VERSION ""

NS_ :

BS_:

BU_: TCU CANedge BMS TempSense

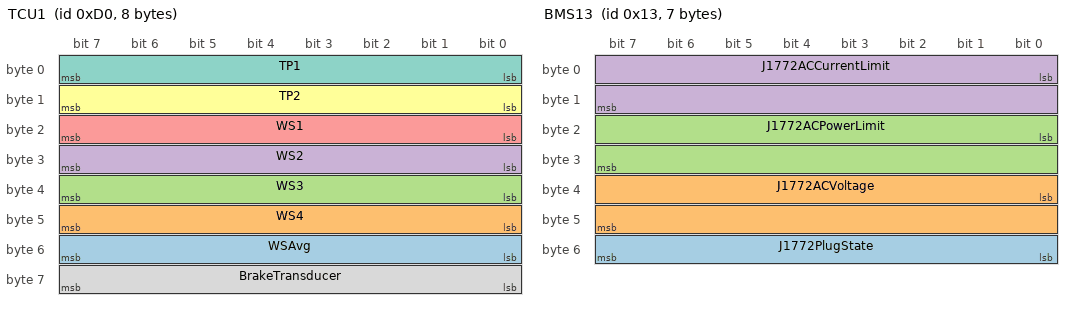
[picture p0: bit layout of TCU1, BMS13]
BO_ 208 TCU1: 8 TCU
 SG_ WSAvg : 48|8@1+ (1,0) [0|255] ""  CANedge
 SG_ WS4 : 40|8@1+ (1,0) [0|255] ""  CANedge
 SG_ WS3 : 32|8@1+ (1,0) [0|255] ""  CANedge
 SG_ WS2 : 24|8@1+ (1,0) [0|255] ""  CANedge
 SG_ WS1 : 16|8@1+ (1,0) [0|255] ""  CANedge
 SG_ TP2 : 8|8@1+ (1,0) [0|100] "%"  CANedge
 SG_ TP1 : 0|8@1+ (1,0) [0|100] "%"  CANedge
 SG_ BrakeTransducer : 56|8@1+ (1,0) [0|0] ""  CANedge

BO_ 20 BMS14: 4 BMS
 SG_ DTCStatus2 : 16|16@1+ (1,0) [0|65535] ""  CANedge
 SG_ DTCStatus1 : 0|16@1+ (1,0) [0|65535] ""  CANedge

BO_ 19 BMS13: 7 BMS
 SG_ J1772PlugState : 48|8@1+ (1,0) [0|4] ""  CANedge
 SG_ J1772ACVoltage : 32|16@1+ (0.1,0) [0|0] "VAC"  CANedge
 SG_ J1772ACPowerLimit : 16|16@1+ (1,0) [0|0] "WattAC"  CANedge
 SG_ J1772ACCurrentLimit : 0|16@1+ (1,0) [0|0] "AmpAC"  CANedge

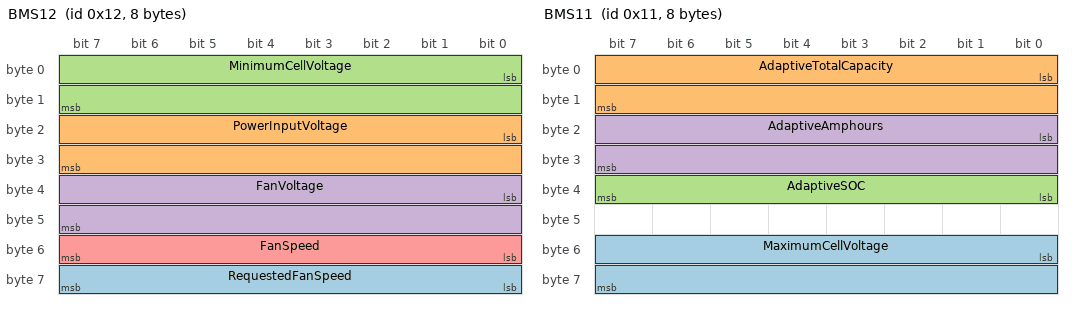
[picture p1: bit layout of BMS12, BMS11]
BO_ 18 BMS12: 8 BMS
 SG_ RequestedFanSpeed : 56|8@1+ (1,0) [0|6] ""  CANedge
 SG_ PowerInputVoltage : 16|16@1+ (0.1,0) [0|0] "V"  CANedge
 SG_ MinimumCellVoltage : 0|16@1+ (0.0001,0) [0|6.5535] "V"  CANedge
 SG_ FanVoltage : 32|16@1+ (0.01,0) [0|0] "V"  CANedge
 SG_ FanSpeed : 48|8@1+ (1,0) [0|6] ""  CANedge

BO_ 17 BMS11: 8 BMS
 SG_ MaximumCellVoltage : 48|16@1+ (0.0001,0) [0|6.5535] "V"  CANedge
 SG_ AdaptiveTotalCapacity : 0|16@1+ (0.1,0) [0|0] "Ah"  CANedge
 SG_ AdaptiveSOC : 32|8@1+ (0.5,0) [0|100] "%"  CANedge
 SG_ AdaptiveAmphours : 16|16@1+ (0.1,0) [0|0] "Ah"  CANedge

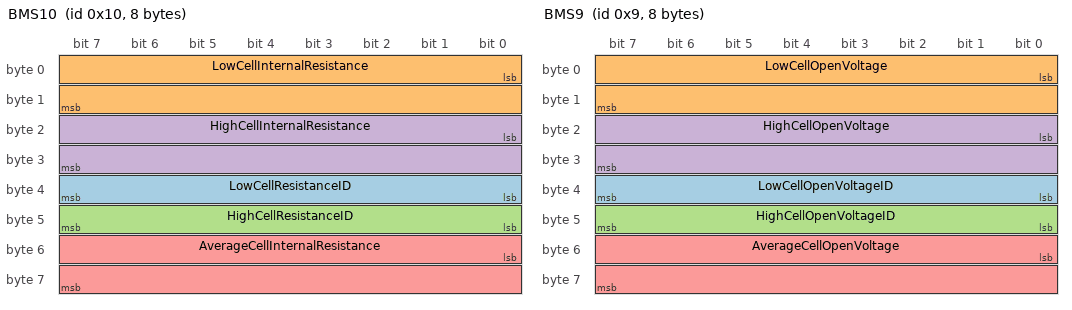
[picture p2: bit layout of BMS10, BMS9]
BO_ 16 BMS10: 8 BMS
 SG_ LowCellResistanceID : 32|8@1+ (1,0) [1|180] ""  CANedge
 SG_ LowCellInternalResistance : 0|16@1+ (0.01,0) [0|0] "mOhm"  CANedge
 SG_ HighCellResistanceID : 40|8@1+ (1,0) [1|180] ""  CANedge
 SG_ HighCellInternalResistance : 16|16@1+ (0.01,0) [0|0] "mOhm"  CANedge
 SG_ AverageCellInternalResistance : 48|16@1+ (0.01,0) [0|0] "mOhm"  CANedge

BO_ 9 BMS9: 8 BMS
 SG_ LowCellOpenVoltageID : 32|8@1+ (1,0) [1|180] ""  CANedge
 SG_ LowCellOpenVoltage : 0|16@1+ (0.0001,0) [0|6.5535] "V"  CANedge
 SG_ HighCellOpenVoltageID : 40|8@1+ (1,0) [1|180] ""  CANedge
 SG_ HighCellOpenVoltage : 16|16@1+ (0.0001,0) [0|6.5535] "V"  CANedge
 SG_ AverageCellOpenVoltage : 48|16@1+ (0.0001,0) [0|6.5535] "V"  CANedge

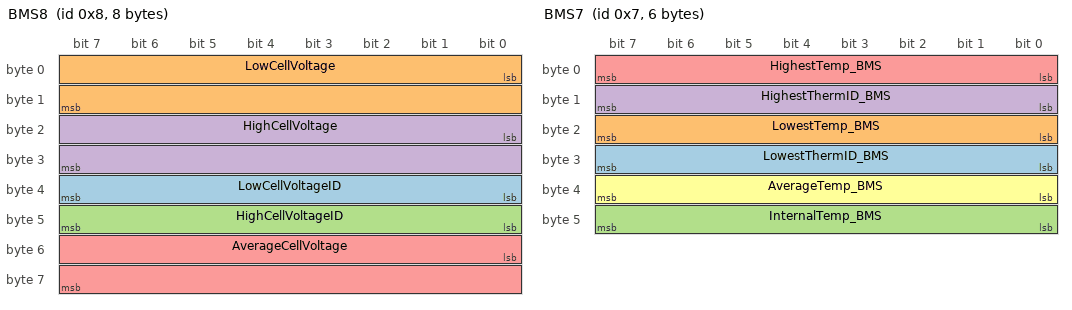
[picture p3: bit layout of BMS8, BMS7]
BO_ 8 BMS8: 8 BMS
 SG_ LowCellVoltageID : 32|8@1+ (1,0) [1|180] ""  CANedge
 SG_ LowCellVoltage : 0|16@1+ (0.0001,0) [0|6.5535] "V"  CANedge
 SG_ HighCellVoltageID : 40|8@1+ (1,0) [1|180] ""  CANedge
 SG_ HighCellVoltage : 16|16@1+ (0.0001,0) [0|6.5535] "V"  CANedge
 SG_ AverageCellVoltage : 48|16@1+ (0.0001,0) [0|6.5535] "V"  CANedge

BO_ 7 BMS7: 6 BMS
 SG_ LowestThermID_BMS : 24|8@1+ (1,0) [1|80] ""  CANedge
 SG_ LowestTemp_BMS : 16|8@1- (1,0) [0|255] "C"  CANedge
 SG_ InternalTemp_BMS : 40|8@1- (1,0) [0|255] "C"  CANedge
 SG_ HighestThermID_BMS : 8|8@1+ (1,0) [1|80] ""  CANedge
 SG_ HighestTemp_BMS : 0|8@1- (1,0) [0|255] "C"  CANedge
 SG_ AverageTemp_BMS : 32|8@1- (1,0) [0|255] "C"  CANedge

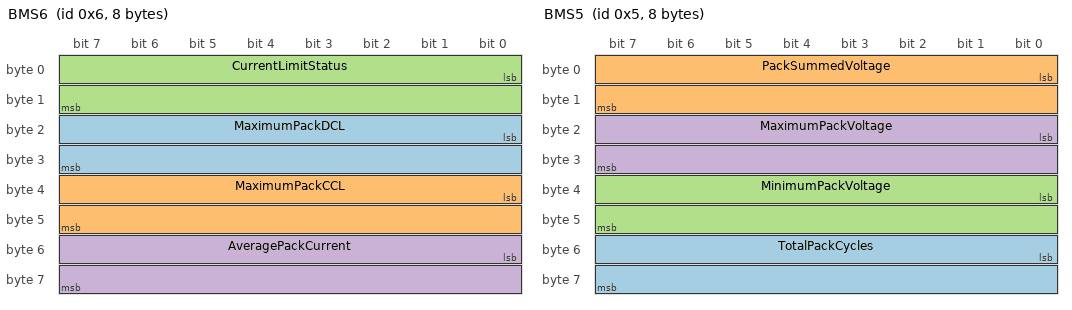
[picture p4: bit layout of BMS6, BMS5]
BO_ 6 BMS6: 8 BMS
 SG_ MaximumPackDCL : 16|16@1+ (1,0) [0|0] "A"  CANedge
 SG_ MaximumPackCCL : 32|16@1+ (1,0) [0|0] "A"  CANedge
 SG_ CurrentLimitStatus : 0|16@1+ (1,0) [0|65535] ""  CANedge
 SG_ AveragePackCurrent : 48|16@1+ (0.1,0) [0|0] "A"  CANedge

BO_ 5 BMS5: 8 BMS
 SG_ TotalPackCycles : 48|16@1+ (1,0) [0|0] "cycle"  CANedge
 SG_ PackSummedVoltage : 0|16@1+ (0.1,0) [0|0] "V"  CANedge
 SG_ MinimumPackVoltage : 32|16@1+ (0.1,0) [0|0] "V"  CANedge
 SG_ MaximumPackVoltage : 16|16@1+ (0.1,0) [0|0] "V"  CANedge

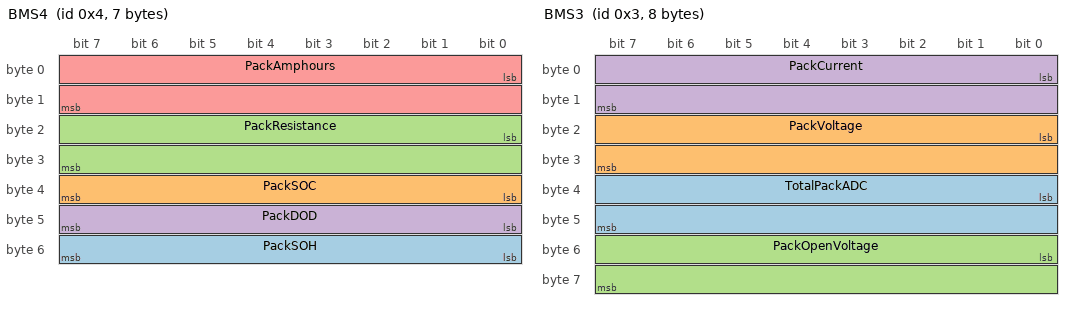
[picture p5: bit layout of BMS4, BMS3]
BO_ 4 BMS4: 7 BMS
 SG_ PackSOH : 48|8@1+ (1,0) [0|100] "%"  CANedge
 SG_ PackSOC : 32|8@1+ (0.5,0) [0|100] "%"  CANedge
 SG_ PackResistance : 16|16@1+ (1,0) [0|0] "mOhm"  CANedge
 SG_ PackDOD : 40|8@1+ (0.5,0) [0|100] "%"  CANedge
 SG_ PackAmphours : 0|16@1+ (0.1,0) [0|0] "Ahr"  CANedge

BO_ 3 BMS3: 8 BMS
 SG_ TotalPackADC : 32|16@1+ (0.1,0) [0|0] "V"  CANedge
 SG_ PackVoltage : 16|16@1+ (0.1,0) [0|0] "V"  CANedge
 SG_ PackOpenVoltage : 48|16@1+ (0.1,0) [0|0] "V"  CANedge
 SG_ PackCurrent : 0|16@1+ (0.1,0) [0|0] "A"  CANedge

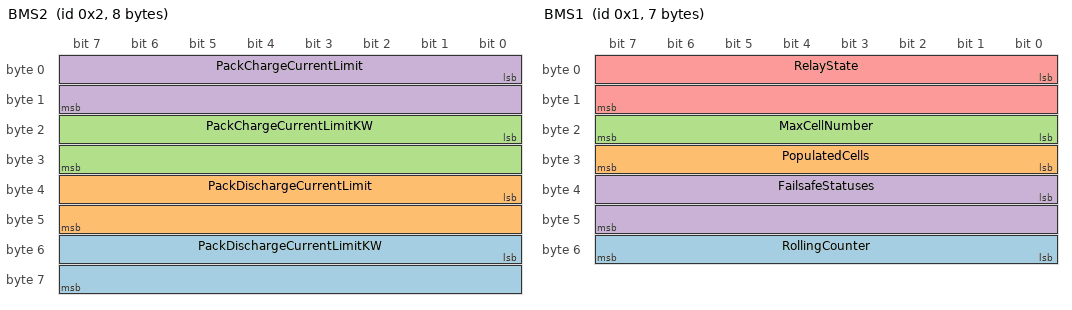
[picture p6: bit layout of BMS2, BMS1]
BO_ 2 BMS2: 8 BMS
 SG_ PackDischargeCurrentLimitKW : 48|16@1+ (0.1,0) [0|0] "kW"  CANedge
 SG_ PackDischargeCurrentLimit : 32|16@1+ (1,0) [0|0] "A"  CANedge
 SG_ PackChargeCurrentLimitKW : 16|16@1+ (0.1,0) [0|0] "kW"  CANedge
 SG_ PackChargeCurrentLimit : 0|16@1+ (1,0) [0|0] "A"  CANedge

BO_ 1 BMS1: 7 BMS
 SG_ RollingCounter : 48|8@1+ (1,0) [0|255] ""  CANedge
 SG_ PopulatedCells : 24|8@1+ (1,0) [0|255] ""  CANedge
 SG_ MaxCellNumber : 16|8@1+ (1,0) [0|255] ""  CANedge
 SG_ FailsafeStatuses : 32|16@1+ (1,0) [0|65535] ""  CANedge
 SG_ RelayState : 0|16@1+ (1,0) [0|65535] ""  CANedge

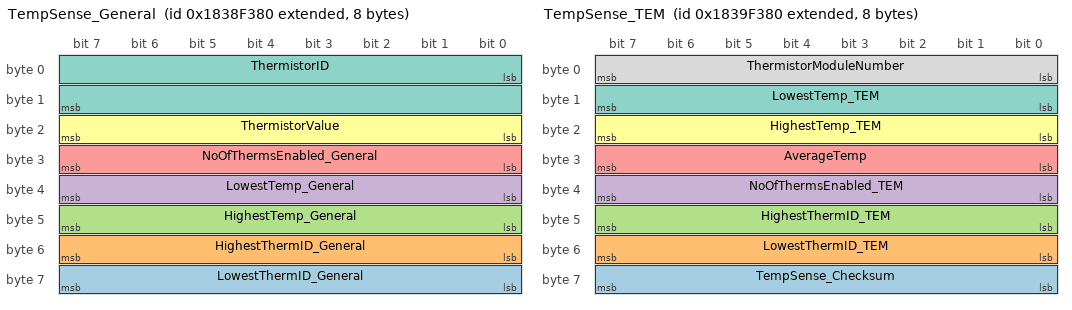
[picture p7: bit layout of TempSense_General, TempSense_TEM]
BO_ 2553869184 TempSense_General: 8 TempSense
 SG_ LowestThermID_General : 56|8@1+ (1,0) [0|79] ""  CANedge
 SG_ HighestThermID_General : 48|8@1+ (1,0) [0|79] ""  CANedge
 SG_ HighestTemp_General : 40|8@1- (1,0) [0|255] "C"  CANedge
 SG_ LowestTemp_General : 32|8@1- (1,0) [0|255] "C"  CANedge
 SG_ NoOfThermsEnabled_General : 24|8@1+ (1,0) [0|80] ""  CANedge
 SG_ ThermistorValue : 16|8@1- (1,0) [0|255] "C"  CANedge
 SG_ ThermistorID : 0|16@1+ (1,0) [0|799] ""  CANedge

BO_ 2553934720 TempSense_TEM: 8 TempSense
 SG_ TempSense_Checksum : 56|8@1+ (1,0) [0|255] ""  CANedge,BMS
 SG_ LowestThermID_TEM : 48|8@1+ (1,0) [0|79] ""  CANedge,BMS
 SG_ HighestThermID_TEM : 40|8@1+ (1,0) [0|79] ""  CANedge,BMS
 SG_ NoOfThermsEnabled_TEM : 32|8@1+ (1,0) [0|80] ""  CANedge,BMS
 SG_ AverageTemp : 24|8@1- (1,0) [0|255] "C"  CANedge,BMS
 SG_ HighestTemp_TEM : 16|8@1- (1,0) [0|255] "C"  CANedge,BMS
 SG_ LowestTemp_TEM : 8|8@1- (1,0) [0|255] "C"  CANedge,BMS
 SG_ ThermistorModuleNumber : 0|8@1+ (1,0) [0|9] ""  CANedge,BMS

CM_ SG_ 6 CurrentLimitStatus "This value is provided so the reasons for why a current limit (either Charge Current Limit or Discharge Current Limit are being reduced by the BMS from the maximum allowable current.";
CM_ SG_ 6 AveragePackCurrent "This is the AVERAGE current pack amperage value for the battery pack. This will report a constant 0 if no current sensor is selected. The average is taken over the last 1 second of operation so it will lag the instantaneous pack current value.";
CM_ SG_ 5 TotalPackCycles "This is the total number of cycles that the battery pack has been put through since the BMS has started keeping track.";
CM_ SG_ 5 PackSummedVoltage "This value is the sum of all the cells being monitored by the BMS. This is different from the Pack Voltage value because that is derived from the redundant total pack voltage sensor rather than summing up all of the cells.";
CM_ SG_ 5 MinimumPackVoltage "This value is the minimum pack voltage that the BMS is using to limit how low the pack voltage is allowed to be pulled down to.";
CM_ SG_ 5 MaximumPackVoltage "This value is the maximum pack voltage that the BMS is using to limit how high the pack voltage can be.";
CM_ SG_ 4 PackDOD "This value reperesents the total pack depth of discharge (that is, the total percent of the battery that has been discharged to this point). This value does not account for any Drift.";
CM_ SG_ 4 PackAmphours "This is the calculated number of amphours remaining in the battery pack. This is used in part to calculate State of Charge.";
CM_ SG_ 3 TotalPackADC "This is the raw voltage value from the total pack voltage sensor (NOT the sum of all the cell voltages). Only available on BMS models that support the separate total pack sensor.";
CM_ SG_ 3 PackCurrent "This is the current pack amperage value for the battery pack. This will report a constant 0 if no current sensor is selected.";
CM_ SG_ 2 PackDischargeCurrentLimitKW "This is the pack Charge Current Limit expressed in kilowatts.";
CM_ SG_ 2 PackChargeCurrentLimitKW "This is the pack Charge Current Limit expressed in kilowatts.";
CM_ SG_ 2 PackChargeCurrentLimit "The value is, by default, reported as a positive value from 0 to whatever the maximum charge current limit is set to.";
CM_ SG_ 1 RollingCounter "This is a sanity-check value that increments automatically by 1 once every 100ms (maximum value is 255, after which it resets to 0 and starts again).";
CM_ SG_ 1 PopulatedCells "This represents the total number of populated (active) cells in the BMS. This is can be equal to or lower than the Max Cell Number.";
CM_ SG_ 1 MaxCellNumber "This value represents the maximum number of cells that the BMS is capable of supporting. This value is determined by what hardware version of the BMS was purchased.";
CM_ SG_ 1 FailsafeStatuses "This parameter contains the status of all the BMS failsafe modes";
CM_ SG_ 1 RelayState "This parameter contains the status (active state) of all the BMS outputs and inputs.";
CM_ BO_ 2553869184 "Thermistor General Broadcast";
CM_ SG_ 2553869184 LowestThermID_General "Orion BMS2: Max number of thermistors supported per expansion module = 80";
CM_ SG_ 2553869184 HighestThermID_General "Orion BMS2: Max number of thermistors supported per expansion module = 80";
CM_ SG_ 2553869184 NoOfThermsEnabled_General "Orion BMS2: Max number of thermistors supported per expansion module = 80";
CM_ SG_ 2553869184 ThermistorID "Orion BMS2:
Max number of thermistor expansion modules supported: 10
Max number of thermistors supported per module: 80
Max thermistors = 800";
CM_ BO_ 2553934720 "Thermistor Module -> BMS Broadcast";
CM_ SG_ 2553934720 LowestThermID_TEM "Orion BMS2: Max number of thermistors supported per expansion module = 80";
CM_ SG_ 2553934720 HighestThermID_TEM "Orion BMS2: Max number of thermistors supported per expansion module = 80";
CM_ SG_ 2553934720 NoOfThermsEnabled_TEM "Orion BMS2: Max number of thermistors supported per expansion module = 80";
CM_ SG_ 2553934720 ThermistorModuleNumber "Orion BMS2: Max number of thermistor modules supported = 10";
BA_DEF_  "BusType" STRING ;
BA_DEF_DEF_  "BusType" "CAN";
